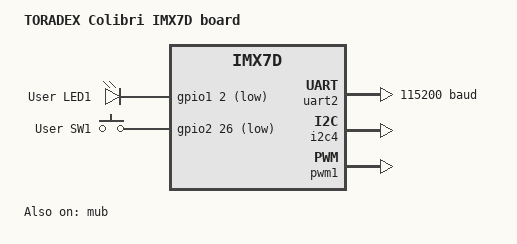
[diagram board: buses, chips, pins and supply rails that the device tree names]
/*
 * Copyright (c) 2017,2019 NXP
 *
 * SPDX-License-Identifier: Apache-2.0
 */

/dts-v1/;

#include <nxp/nxp_imx7d_m4.dtsi>

/ {
	model = "TORADEX Colibri IMX7D board";
	compatible = "nxp,mcimx7d_m4";

	aliases {
		led0   = &green_led;
		sw0    = &user_switch_1;
	};

	chosen {
		zephyr,flash = &tcml_code;
		zephyr,sram = &tcmu_sys;
		zephyr,console = &uart2;
		zephyr,shell-uart = &uart2;
	};

	leds {
		compatible = "gpio-leds";
		green_led: led_0 {
			gpios = <&gpio1 2 GPIO_ACTIVE_LOW>;
			label = "User LED1";
		};
	};

	gpio_keys {
		compatible = "gpio-keys";
		user_switch_1: user_sw_1 {
			gpios = <&gpio2 26 GPIO_ACTIVE_LOW>;
			label = "User SW1";
		};
	};
};

&uart2 {
	status = "okay";
	current-speed = <115200>;
	modem-mode = <64>;
};

&gpio1 {
	status = "okay";
};

&gpio2 {
	status = "okay";
};

&i2c4 {
	status = "okay";
};

&pwm1 {
	status = "okay";
};

&mub {
	status = "okay";
};
